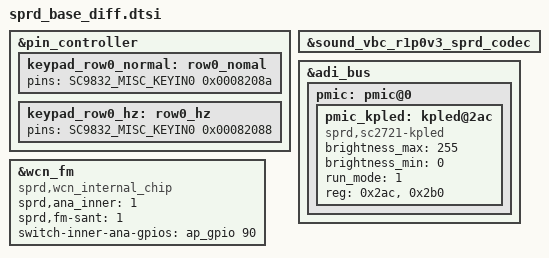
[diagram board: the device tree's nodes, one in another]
/*
 * this file is ued to change sprd dtsi which can't be changed by overlay
 * such as /delete-node/ /delete-property/ and alises
 */

#include "zte_lcd_spi_panel.dtsi"
&pin_controller {
		/* for matrix keypad */
	keypad_row0_normal: row0_nomal {
		pins = <SC9832_MISC_KEYIN0 0x0008208a>;
	};
	keypad_row0_hz: row0_hz {
		pins = <SC9832_MISC_KEYIN0 0x00082088>;
	};
};

&sound_vbc_r1p0v3_sprd_codec {
	/delete-property/ sprd,smartamp-boost-names;
	/delete-property/ sprd,smartamp-boost-gpios;
};

&adi_bus {
	pmic: pmic@0 {
	pmic_kpled: kpled@2ac {
			compatible = "sprd,sc2721-kpled";
			brightness_max = <255>;
			brightness_min = <0>;
			run_mode = <1>; /* default current mode */
			reg = <0x2ac>,<0x2b0>;
			status = "ok";
		};
		};
	};

/* Add FM short antenna (inner antenna)*/
&wcn_fm {
	compatible = "sprd,wcn_internal_chip";
	sprd,ana_inner = <1>;
	sprd,fm-sant = <1>;
	switch-inner-ana-gpios = <&ap_gpio 90 0>; //gipo sant
};
